# ing920 register map
Vendor: INGChips; Series: ing920xx; File version: 1.0
CPU: CM3 r2p1, little endian, no MPU, no FPU, 2 interrupt priority bits
Registers are 32-bit, read-write, reset 0x0 unless marked. A register's access mark holds for its fields unless they carry their own. Offsets are from the block's base; [hi:lo] are bit positions; {n}, {i} and the like mark numbered series.

## pte_bus
Base 0x40018000
{0x0+4i} REG_P1_TASK{i} (i=0..5) — reg description:
  [0] peri1_task{i}
{0x20+4i} REG_P1_SUB_TASK{i} (i=0..5) — reg description:
  [7:0] peri1_sub_task{i}_chidx
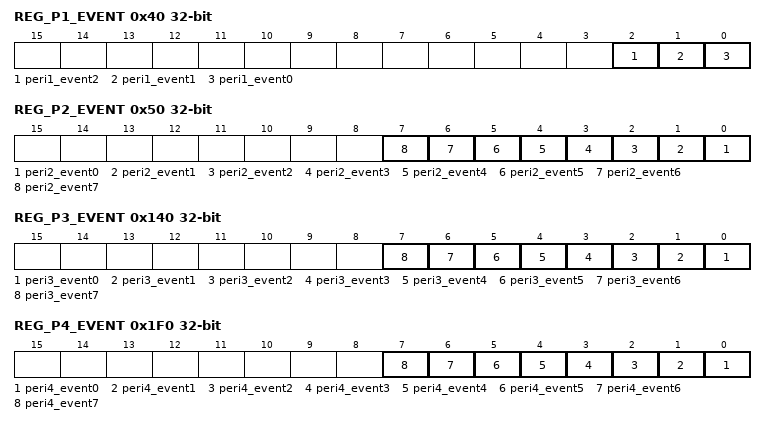
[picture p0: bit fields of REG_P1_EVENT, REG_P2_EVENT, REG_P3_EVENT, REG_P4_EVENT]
0x40 REG_P1_EVENT — reg description:
  [2] peri1_event2 — reg description:
  [1] peri1_event1 — reg description:
  [0] peri1_event0 — reg description:
{0x44+4i} REG_P1_PUB_EVENT{i} (i=0..2) — reg description:
  [7:0] peri1_pub_event{i}_chidx
0x50 REG_P2_EVENT — reg description:
  [n] peri2_event{n} (n=0..7) — reg description:
{0x54+4i} REG_P2_PUB_EVENT{i} (i=0..7) — reg description:
  [7:0] peri2_pub_event{i}_chidx
{0x80+4i} REG_P3_TASK{i} (i=0..23) — reg description:
  [0] peri3_task{i}
{0xE0+4i} REG_P3_SUB_TASK{i} (i=0..23) — reg description:
  [7:0] peri3_sub_task{i}_chidx
0x140 REG_P3_EVENT — reg description:
  [n] peri3_event{n} (n=0..7) — reg description:
{0x144+4i} REG_P3_PUB_EVENT{i} (i=0..7) — reg description:
  [7:0] peri3_pub_event{i}_chidx
{0x170+4i} REG_P4_TASK{i} (i=0..15) — reg description:
  [0] peri4_task{i}
{0x1B0+4i} REG_P4_SUB_TASK{i} (i=0..15) — reg description:
  [7:0] peri4_sub_task{i}_chidx
0x1F0 REG_P4_EVENT — reg description:
  [n] peri4_event{n} (n=0..7) — reg description:
{0x1F4+4i} REG_P4_PUB_EVENT{i} (i=0..7) — reg description:
  [7:0] peri4_pub_event{i}_chidx
0x220 REG_P5_TASK0 — reg description:
  [0] peri5_task0
0x224 REG_P5_TASK1 — reg description:
  [0] peri5_task1
0x228 REG_P5_SUB_TASK0 — reg description:
  [7:0] peri5_sub_task0_chidx
0x22C REG_P5_SUB_TASK1 — reg description:
  [7:0] peri5_sub_task1_chidx
0x230 REG_P5_EVENT — reg description:
  [0] peri5_event0
0x234 REG_P5_PUB_EVENT0 — reg description:
  [7:0] peri5_pub_event0_chidx
0x240 REG_P6_TASK0 — reg description:
  [0] peri6_task0
0x244 REG_P6_SUB_TASK0 — reg description:
  [7:0] peri6_sub_task0_chidx
0x248 REG_P6_EVENT — reg description:
  [0] peri6_event0
0x24C REG_P6_PUB_EVENT0 — reg description:
  [7:0] peri6_pub_event0_chidx
{0x250+4i} REG_P7_TASK{i} (i=0..2) — reg description:
  [0] peri7_task{i}
{0x260+4i} REG_P7_SUB_TASK{i} (i=0..2) — reg description:
  [7:0] peri7_sub_task{i}_chidx
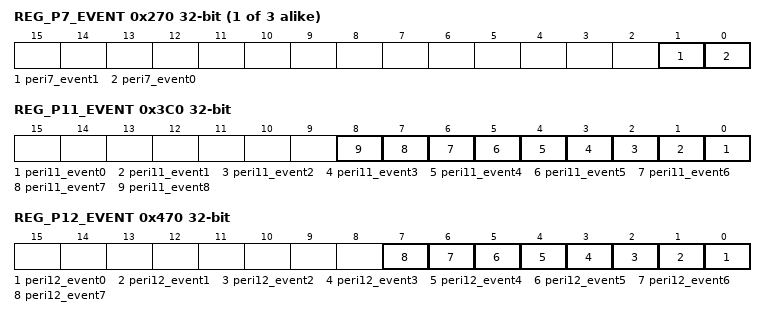
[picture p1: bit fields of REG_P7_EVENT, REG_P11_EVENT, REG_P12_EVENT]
{0x120+0x30*i} REG_P{i}_EVENT (i=7..9) — reg description:
  [1] peri{i}_event1 — reg description:
  [0] peri{i}_event0 — reg description:
0x274 REG_P7_PUB_EVENT0 — reg description:
  [7:0] peri7_pub_event0_chidx
0x278 REG_P7_PUB_EVENT1 — reg description:
  [7:0] peri7_pub_event1_chidx
{0x280+4i} REG_P8_TASK{i} (i=0..3) — reg description:
  [0] peri8_task{i}
{0x290+4i} REG_P8_SUB_TASK{i} (i=0..3) — reg description:
  [7:0] peri8_sub_task{i}_chidx
0x2A4 REG_P8_PUB_EVENT0 — reg description:
  [7:0] peri8_pub_event0_chidx
0x2A8 REG_P8_PUB_EVENT1 — reg description:
  [7:0] peri8_pub_event1_chidx
{0x2B0+4i} REG_P9_TASK{i} (i=0..3) — reg description:
  [0] peri9_task{i}
{0x2C0+4i} REG_P9_SUB_TASK{i} (i=0..3) — reg description:
  [7:0] peri9_sub_task{i}_chidx
0x2D4 REG_P9_PUB_EVENT0 — reg description:
  [7:0] peri9_pub_event0_chidx
0x2D8 REG_P9_PUB_EVENT1 — reg description:
  [7:0] peri9_pub_event1_chidx
0x2E0 REG_P10_TASK0 — reg description:
  [0] peri10_task0
0x2E4 REG_P10_TASK1 — reg description:
  [0] peri10_task1
0x2E8 REG_P10_SUB_TASK0 — reg description:
  [7:0] peri10_sub_task0_chidx
0x2EC REG_P10_SUB_TASK1 — reg description:
  [7:0] peri10_sub_task1_chidx
0x2F0 REG_P10_EVENT — reg description:
  [0] peri10_event0
0x2F4 REG_P10_PUB_EVENT0 — reg description:
  [7:0] peri10_pub_event0_chidx
{0x300+4i} REG_P11_TASK{i} (i=0..20) — reg description:
  [0] peri11_task{i}
{0x360+4i} REG_P11_SUB_TASK{i} (i=0..20) — reg description:
  [7:0] peri11_sub_task{i}_chidx
0x3C0 REG_P11_EVENT — reg description:
  [n] peri11_event{n} (n=0..8) — reg description:
{0x3C4+4i} REG_P11_PUB_EVENT{i} (i=0..8) — reg description:
  [7:0] peri11_pub_event{i}_chidx
{0x3F0+4i} REG_P12_TASK{i} (i=0..15) — reg description:
  [0] peri12_task{i}
{0x430+4i} REG_P12_SUB_TASK{i} (i=0..15) — reg description:
  [7:0] peri12_sub_task{i}_chidx
0x470 REG_P12_EVENT — reg description:
  [n] peri12_event{n} (n=0..7) — reg description:
{0x474+4i} REG_P12_PUB_EVENT{i} (i=0..7) — reg description:
  [7:0] peri12_pub_event{i}_chidx
{0x4A0+4i} REG_P13_TASK{i} (i=0..3) — reg description:
  [0] peri13_task{i}
{0x4B0+4i} REG_P13_SUB_TASK{i} (i=0..3) — reg description:
  [7:0] peri13_sub_task{i}_chidx
0x4C0 REG_P14_TASK0 — reg description:
  [0] peri14_task0
0x4C4 REG_P14_SUB_TASK0 — reg description:
  [7:0] peri14_sub_task0_chidx
0x4C8 REG_P14_TASK1 — reg description:
  [0] peri14_task1
0x4CC REG_P14_SUB_TASK1 — reg description:
  [7:0] peri14_sub_task1_chidx
0x4F0 REG_P14_EVENT — reg description:
  [0] peri14_event0
0x4F4 REG_P14_PUB_EVENT0 — reg description:
  [7:0] peri14_pub_event0_chidx
